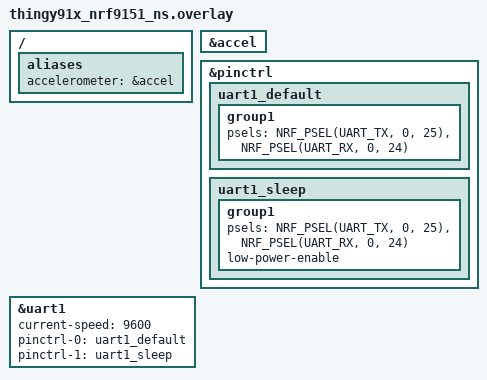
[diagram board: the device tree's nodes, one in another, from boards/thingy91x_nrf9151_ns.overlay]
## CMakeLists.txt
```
cmake_minimum_required(VERSION 3.20.0)

set(CMAKE_CXX_STANDARD 11)
set(CMAKE_CXX_STANDARD_REQUIRED ON)

find_package(Zephyr REQUIRED HINTS $ENV{ZEPHYR_BASE})

project(firmware-nordic-thingy91x)

zephyr_compile_definitions(PROJECT_NAME=${PROJECT_NAME})

# Needed for colorful output
zephyr_compile_options(-fdiagnostics-color=always)

# Do not quantize filterbank
# Enable manual loop unrolling in DSP functions
add_definitions(-DEIDSP_QUANTIZE_FILTERBANK=0
                -DARM_MATH_LOOPUNROLL
                )

# Add all required source files
add_subdirectory(ei-model/edge-impulse-sdk/cmake/zephyr)
add_subdirectory(firmware-sdk)
add_subdirectory(src/inference)
add_subdirectory(src/sensors)
add_subdirectory(src)

# Include directories (everything in the SDK is already included here)
target_include_directories(app PRIVATE .)
target_include_directories(app PRIVATE ei-model)

# Use GLOB to include model files, because model file names differes whether model is EON compiled or not
RECURSIVE_FIND_FILE(MODEL_FILES ei-model/tflite-model "*.cpp")
target_sources(app PRIVATE ${MODEL_FILES})
```

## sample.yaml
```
sample:
  name: Fall Detection GPS Emergency Alert System
  description: Edge Impulse fall detection with LoRaWAN GPS emergency alerts
tests:
  sample.fall_detection_gps_tracker:
    integration_platforms:
      - thingy91x/nrf9151/ns
    tags:
      - sensors
      - accelerometer
      - gnss
      - lorawan
      - ml
      - fall_detection
      - emergency_alert
    filter: CONFIG_ADXL367 and CONFIG_NRF_MODEM_LIB and CONFIG_UART_ASYNC_API
    harness: keyboard
```

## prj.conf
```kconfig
# /* The Clear BSD License
#  *
#  * Copyright (c) 2025 EdgeImpulse Inc.
#  * All rights reserved.
#  *
#  * Redistribution and use in source and binary forms, with or without
#  * modification, are permitted (subject to the limitations in the disclaimer
#  * below) provided that the following conditions are met:
#  *
#  *   * Redistributions of source code must retain the above copyright notice,
#  *   this list of conditions and the following disclaimer.
#  *
#  *   * Redistributions in binary form must reproduce the above copyright
#  *   notice, this list of conditions and the following disclaimer in the
#  *   documentation and/or other materials provided with the distribution.
#  *
#  *   * Neither the name of the copyright holder nor the names of its
#  *   contributors may be used to endorse or promote products derived from this
#  *   software without specific prior written permission.
#  *
#  * NO EXPRESS OR IMPLIED LICENSES TO ANY PARTY'S PATENT RIGHTS ARE GRANTED BY
#  * THIS LICENSE. THIS SOFTWARE IS PROVIDED BY THE COPYRIGHT HOLDERS AND
#  * CONTRIBUTORS "AS IS" AND ANY EXPRESS OR IMPLIED WARRANTIES, INCLUDING, BUT NOT
#  * LIMITED TO, THE IMPLIED WARRANTIES OF MERCHANTABILITY AND FITNESS FOR A
#  * PARTICULAR PURPOSE ARE DISCLAIMED. IN NO EVENT SHALL THE COPYRIGHT HOLDER OR
#  * CONTRIBUTORS BE LIABLE FOR ANY DIRECT, INDIRECT, INCIDENTAL, SPECIAL,
#  * EXEMPLARY, OR CONSEQUENTIAL DAMAGES (INCLUDING, BUT NOT LIMITED TO,
#  * PROCUREMENT OF SUBSTITUTE GOODS OR SERVICES; LOSS OF USE, DATA, OR PROFITS; OR
#  * BUSINESS INTERRUPTION) HOWEVER CAUSED AND ON ANY THEORY OF LIABILITY, WHETHER
#  * IN CONTRACT, STRICT LIABILITY, OR TORT (INCLUDING NEGLIGENCE OR OTHERWISE)
#  * ARISING IN ANY WAY OUT OF THE USE OF THIS SOFTWARE, EVEN IF ADVISED OF THE
#  * POSSIBILITY OF SUCH DAMAGE.
#  */

#
# Combined EdgeImpulse + LoRaWAN + GNSS Configuration
# Using working LoRa project as base for GPS functionality
#

# Bootloader (from working LoRa base)
CONFIG_BOOTLOADER_MCUBOOT=y

# Basic system configuration (optimized from working EdgeImpulse + LoRa + GPS)
CONFIG_MAIN_STACK_SIZE=4096
CONFIG_SYSTEM_WORKQUEUE_STACK_SIZE=4096
CONFIG_HEAP_MEM_POOL_SIZE=60000

# UART configuration (from working LoRa base - keep async for LoRa-E5)
CONFIG_SERIAL=y
CONFIG_UART_NRFX=y
CONFIG_UART_ASYNC_API=y

# GPIO for LED control (from working LoRa base)
CONFIG_GPIO=y

# Standard C library support (EdgeImpulse + working LoRa base)
CONFIG_NEWLIB_LIBC=y
CONFIG_NEWLIB_LIBC_NANO=y
CONFIG_NEWLIB_LIBC_FLOAT_PRINTF=y
CONFIG_ASSERT=y
CONFIG_REBOOT=y
CONFIG_FPU=y
CONFIG_CPP=y
CONFIG_GLIBCXX_LIBCPP=y
CONFIG_BOOT_BANNER=n
CONFIG_COMPILER_WARNINGS_AS_ERRORS=n

# Logging configuration (from working LoRa base)
CONFIG_LOG=y
CONFIG_LOG_DEFAULT_LEVEL=3
CONFIG_PRINTK=y
CONFIG_CONSOLE=y
CONFIG_UART_CONSOLE=y

# EdgeImpulse specific
CONFIG_LOG_MODE_DEFERRED=y
CONFIG_CBPRINTF_PACKAGE_LOG_LEVEL_OFF=y
CONFIG_FLASH_LOG_LEVEL_OFF=y
CONFIG_SENSOR_LOG_LEVEL_OFF=y
CONFIG_HW_STACK_PROTECTION=y

# Disable MCUboot DFU -- incompatible with static partitions (EdgeImpulse)
CONFIG_SECURE_BOOT=n

# Flash - Used in FOTA, settings and storage for P-GPS (EdgeImpulse)
CONFIG_FLASH=y
CONFIG_FLASH_PAGE_LAYOUT=y
CONFIG_FLASH_MAP=y
CONFIG_STREAM_FLASH=y
CONFIG_MPU_ALLOW_FLASH_WRITE=y

# LEDs (EdgeImpulse)
CONFIG_LED=y
CONFIG_LED_GPIO=y

# Sensors (EdgeImpulse)
CONFIG_SENSOR=y
CONFIG_ADXL367=y

# Power Management (EdgeImpulse)
CONFIG_REGULATOR=y

# GNSS support (EXACT from working LoRa project)
CONFIG_NRF_MODEM_LIB=y
CONFIG_LTE_LINK_CONTROL=y
CONFIG_LTE_NETWORK_MODE_LTE_M_GPS=y

# Networking for GNSS (EXACT copy from working LoRa project)
CONFIG_NETWORKING=y
CONFIG_NET_SOCKETS_OFFLOAD=y
CONFIG_NET_SOCKETS=y
CONFIG_NET_NATIVE=n

# POSIX support - minimal to avoid syscall issues
CONFIG_POSIX_API=n

# Basic AT Host support (from working LoRa project)
CONFIG_AT_HOST_LIBRARY=y

# Watchdog for reliability (from working LoRa project)
CONFIG_WATCHDOG=y

# EdgeImpulse specific - polling support for GNSS event handling
CONFIG_POLL=y

# Modem info (EdgeImpulse)
CONFIG_MODEM_INFO=y
```

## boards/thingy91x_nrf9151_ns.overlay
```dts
/*
 * Copyright (c) 2021 Nordic Semiconductor ASA
 *
 * SPDX-License-Identifier: LicenseRef-Nordic-5-Clause
 */

/ {
	aliases {
		accelerometer = &accel;
	};
};

&accel {
	status = "okay";
};

// UART1 configuration for LoRa-E5 module
&pinctrl {
    uart1_default: uart1_default {
        group1 {
            psels = <NRF_PSEL(UART_TX, 0, 25)>,
                    <NRF_PSEL(UART_RX, 0, 24)>;
        };
    };

    uart1_sleep: uart1_sleep {
        group1 {
            psels = <NRF_PSEL(UART_TX, 0, 25)>,
                    <NRF_PSEL(UART_RX, 0, 24)>;
            low-power-enable;
        };
    };
};

&uart1 {
    status = "okay";
    current-speed = <9600>;
    pinctrl-0 = <&uart1_default>;
    pinctrl-1 = <&uart1_sleep>;
    pinctrl-names = "default", "sleep";
};
```

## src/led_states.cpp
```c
#include "led_states.h"
#include <zephyr/logging/log.h>

LOG_MODULE_REGISTER(led_states, CONFIG_LOG_DEFAULT_LEVEL);

// Global variables
static const struct device *gpio_dev = NULL;
static bool led_initialized = false;
static bool background_task_running __attribute__((unused)) = false;
static led_state_t current_state = LED_STATE_ALL_OFF;

// Background thread for LED patterns (unused for now)
static struct k_thread led_thread __attribute__((unused));
static K_THREAD_STACK_DEFINE(led_thread_stack, 1024) __attribute__((unused));

// Mutex for LED operations
K_MUTEX_DEFINE(led_mutex);

// Initialize LED subsystem
void led_init(void)
{
    gpio_dev = DEVICE_DT_GET(DT_NODELABEL(gpio0));
    if (!device_is_ready(gpio_dev)) {
        LOG_ERR("GPIO device not ready for LEDs");
        return;
    }

    // Configure LED pins as outputs (active low)
    gpio_pin_configure(gpio_dev, LED_RED_PIN, GPIO_OUTPUT_INACTIVE);
    gpio_pin_configure(gpio_dev, LED_GREEN_PIN, GPIO_OUTPUT_INACTIVE);
    gpio_pin_configure(gpio_dev, LED_BLUE_PIN, GPIO_OUTPUT_INACTIVE);

    led_initialized = true;
    LOG_INF("LED system initialized");
}

// Set individual LED color (Thingy:91 X LEDs are active HIGH)
void led_set_color(bool red, bool green, bool blue)
{
    if (!led_initialized) return;

    k_mutex_lock(&led_mutex, K_FOREVER);

    gpio_pin_set(gpio_dev, LED_RED_PIN, red ? 1 : 0);    // Active HIGH: 1=ON, 0=OFF
    gpio_pin_set(gpio_dev, LED_GREEN_PIN, green ? 1 : 0); // Active HIGH: 1=ON, 0=OFF
    gpio_pin_set(gpio_dev, LED_BLUE_PIN, blue ? 1 : 0);   // Active HIGH: 1=ON, 0=OFF

    k_mutex_unlock(&led_mutex);
}

// Turn off all LEDs
void led_all_off(void)
{
    led_set_color(false, false, false);
}

// Simple blink functions for specific colors
void led_blink_red(uint32_t count, uint32_t duration_ms, uint32_t delay_ms)
{
    for (uint32_t i = 0; i < count; i++) {
        led_set_color(true, false, false);
        k_msleep(duration_ms);
        led_all_off();
        if (i < count - 1) k_msleep(delay_ms);
    }
}

void led_blink_green(uint32_t count, uint32_t duration_ms, uint32_t delay_ms)
{
    for (uint32_t i = 0; i < count; i++) {
        led_set_color(false, true, false);
        k_msleep(duration_ms);
        led_all_off();
        if (i < count - 1) k_msleep(delay_ms);
    }
}

void led_blink_blue(uint32_t count, uint32_t duration_ms, uint32_t delay_ms)
{
    for (uint32_t i = 0; i < count; i++) {
        led_set_color(false, false, true);
        k_msleep(duration_ms);
        led_all_off();
        if (i < count - 1) k_msleep(delay_ms);
    }
}

void led_blink_yellow(uint32_t count, uint32_t duration_ms, uint32_t delay_ms)
{
    for (uint32_t i = 0; i < count; i++) {
        led_set_color(true, true, false);  // Red + Green = Yellow
        k_msleep(duration_ms);
        led_all_off();
        if (i < count - 1) k_msleep(delay_ms);
    }
}

void led_blink_cyan(uint32_t count, uint32_t duration_ms, uint32_t delay_ms)
{
    for (uint32_t i = 0; i < count; i++) {
        led_set_color(false, true, true);  // Green + Blue = Cyan
        k_msleep(duration_ms);
        led_all_off();
        if (i < count - 1) k_msleep(delay_ms);
    }
}

void led_blink_magenta(uint32_t count, uint32_t duration_ms, uint32_t delay_ms)
{
    for (uint32_t i = 0; i < count; i++) {
        led_set_color(true, false, true);  // Red + Blue = Magenta
        k_msleep(duration_ms);
        led_all_off();
        if (i < count - 1) k_msleep(delay_ms);
    }
}

void led_blink_white(uint32_t count, uint32_t duration_ms, uint32_t delay_ms)
{
    for (uint32_t i = 0; i < count; i++) {
        led_set_color(true, true, true);  // All colors = White
        k_msleep(duration_ms);
        led_all_off();
        if (i < count - 1) k_msleep(delay_ms);
    }
}

// Solid color functions
void led_solid_green(uint32_t duration_ms)
{
    led_set_color(false, true, false);
    k_msleep(duration_ms);
    led_all_off();
}

void led_solid_red(uint32_t duration_ms)
{
    led_set_color(true, false, false);
    k_msleep(duration_ms);
    led_all_off();
}

// Emergency flash pattern
void led_emergency_flash(void)
{
    // Urgent red flashing pattern
    for (int i = 0; i < 10; i++) {
        led_set_color(true, false, false);
        k_msleep(100);
        led_all_off();
        k_msleep(100);
    }
    k_msleep(500);
    for (int i = 0; i < 10; i++) {
        led_set_color(true, false, false);
        k_msleep(100);
        led_all_off();
        k_msleep(100);
    }
}

// Breathing effect for operational state
void led_breathing_effect(void)
{
    // Gentle green breathing effect
    for (int brightness = 0; brightness < 100; brightness += 5) {
        led_set_color(false, true, false);
        k_msleep(10);
        led_all_off();
        k_msleep(50);
    }
    for (int brightness = 100; brightness > 0; brightness -= 5) {
        led_set_color(false, true, false);
        k_msleep(10);
        led_all_off();
        k_msleep(50);
    }
}

// Main LED state function
void led_set_state(led_state_t state)
{
    if (!led_initialized) return;

    current_state = state;

    switch (state) {
        case LED_STATE_SYSTEM_INIT:
            // White blink - system initializing
            led_blink_white(3, 200, 200);
            break;

        case LED_STATE_SYSTEM_READY:
            // Solid green for 2 seconds - all systems ready
            led_solid_green(2000);
            break;

        case LED_STATE_SYSTEM_ERROR:
            // Solid red - critical error
            led_set_color(true, false, false);
            break;

        // LoRa states
        case LED_STATE_LORA_INITIALIZING:
            // Yellow slow blink
            led_blink_yellow(5, 300, 500);
            break;

        case LED_STATE_LORA_INIT_SUCCESS:
            // Green blink
            led_blink_green(2, 200, 200);
            break;

        case LED_STATE_LORA_INIT_FAILED:
            // Red fast blink
            led_blink_red(5, 100, 100);
            break;

        case LED_STATE_LORA_JOINING:
            // Orange slow blink (red + green with timing)
            for (int i = 0; i < 5; i++) {
                led_set_color(true, true, false);
                k_msleep(400);
                led_all_off();
                k_msleep(600);
            }
            break;

        case LED_STATE_LORA_JOINED:
            // Green double blink
            led_blink_green(2, 150, 150);
            k_msleep(300);
            led_blink_green(2, 150, 150);
            break;

        case LED_STATE_LORA_JOIN_FAILED:
            // Red double blink
            led_blink_red(2, 150, 150);
            k_msleep(300);
            led_blink_red(2, 150, 150);
            break;

        case LED_STATE_LORA_SENDING:
            // Blue fast blink
            led_blink_blue(8, 50, 50);
            break;

        case LED_STATE_LORA_SEND_SUCCESS:
            // Green triple blink
            led_blink_green(3, 100, 100);
            break;

        case LED_STATE_LORA_SEND_FAILED:
            // Red triple blink
            led_blink_red(3, 100, 100);
            break;

        // GPS states
        case LED_STATE_GPS_INITIALIZING:
            // Cyan slow blink
            led_blink_cyan(5, 300, 500);
            break;

        case LED_STATE_GPS_INIT_SUCCESS:
            // Green blink
            led_blink_green(1, 300, 0);
            break;

        case LED_STATE_GPS_INIT_FAILED:
            // Red blink
            led_blink_red(1, 300, 0);
            break;

        case LED_STATE_GPS_SEARCHING:
            // Purple slow blink
            led_blink_magenta(1, 500, 1000);
            break;

        case LED_STATE_GPS_FIX_ACQUIRED:
            // Green solid for 2 seconds
            led_solid_green(2000);
            break;

        case LED_STATE_GPS_FIX_LOST:
            // Orange blink
            for (int i = 0; i < 3; i++) {
                led_set_color(true, true, false);
                k_msleep(200);
                led_all_off();
                k_msleep(200);
            }
            break;

        case LED_STATE_GPS_TIMEOUT:
            // Red slow blink
            led_blink_red(3, 500, 500);
            break;

        // ML states
        case LED_STATE_ML_INITIALIZING:
            // Magenta slow blink
            led_blink_magenta(5, 300, 300);
            break;

        case LED_STATE_ML_READY:
            // Green single blink
            led_blink_green(1, 200, 0);
            break;

        case LED_STATE_ML_INFERENCING:
            // Blue very fast blink
            led_blink_blue(1, 50, 0);
            break;

        case LED_STATE_ML_IDLE_DETECTED:
            // Blue dim (short pulse)
            led_blink_blue(1, 10, 0);
            break;

        case LED_STATE_ML_ACTIVE_DETECTED:
            // Blue bright (longer pulse)
            led_blink_blue(1, 100, 0);
            break;

        case LED_STATE_ML_ERROR:
            // Red blink
            led_blink_red(1, 200, 0);
            break;

        // Emergency states
        case LED_STATE_FALL_DETECTED:
            // Urgent red flashing
            led_emergency_flash();
            break;

        case LED_STATE_EMERGENCY_ALERT_SENT:
            // Red + Green alternating
            for (int i = 0; i < 6; i++) {
                led_set_color(true, false, false);
                k_msleep(150);
                led_set_color(false, true, false);
                k_msleep(150);
            }
            led_all_off();
            break;

        case LED_STATE_EMERGENCY_ALERT_FAILED:
            // Red continuous for 3 seconds
            led_set_color(true, false, false);
            k_msleep(3000);
            led_all_off();
            break;

        case LED_STATE_EMERGENCY_COOLDOWN:
            // Orange dim
            led_set_color(true, true, false);
            k_msleep(100);
            led_all_off();
            break;

        // Location transmission states
        case LED_STATE_LOCATION_ROUTINE_SENT:
            // Blue triple blink
            led_blink_blue(3, 100, 100);
            break;

        case LED_STATE_LOCATION_EMERGENCY_SENT:
            // Red + Blue alternating
            for (int i = 0; i < 4; i++) {
                led_set_color(true, false, false);
                k_msleep(100);
                led_set_color(false, false, true);
                k_msleep(100);
            }
            led_all_off();
            break;

        case LED_STATE_LOCATION_SEND_FAILED:
            // Red + Orange alternating
            for (int i = 0; i < 3; i++) {
                led_set_color(true, false, false);
                k_msleep(150);
                led_set_color(true, true, false);
                k_msleep(150);
            }
            led_all_off();
            break;

        case LED_STATE_ALL_OFF:
        default:
            led_all_off();
            break;
    }
}
```

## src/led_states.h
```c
#ifndef LED_STATES_H
#define LED_STATES_H

#include <zephyr/kernel.h>
#include <zephyr/drivers/gpio.h>

#ifdef __cplusplus
extern "C" {
#endif

// LED State Management System for Fall Detection + GPS Emergency Alert System

// LED pin definitions (Thingy:91 X) - corrected mapping: P29=RED, P31=GREEN, P30=BLUE
#define LED_RED_PIN   29  // P0.29 controls RED LED
#define LED_GREEN_PIN 31  // P0.31 controls GREEN LED
#define LED_BLUE_PIN  30  // P0.30 controls BLUE LED

// System state definitions
typedef enum {
    // System states
    LED_STATE_SYSTEM_INIT,              // White (all colors) - System initializing
    LED_STATE_SYSTEM_READY,             // Green solid - All systems operational
    LED_STATE_SYSTEM_ERROR,             // Red solid - Critical system error

    // LoRa states
    LED_STATE_LORA_INITIALIZING,        // Yellow slow blink - LoRa module initializing
    LED_STATE_LORA_INIT_SUCCESS,        // Green blink - LoRa initialized successfully
    LED_STATE_LORA_INIT_FAILED,         // Red fast blink - LoRa initialization failed
    LED_STATE_LORA_JOINING,             // Orange slow blink - Joining LoRaWAN network
    LED_STATE_LORA_JOINED,              // Green double blink - Successfully joined network
    LED_STATE_LORA_JOIN_FAILED,         // Red double blink - Failed to join network
    LED_STATE_LORA_SENDING,             // Blue fast blink - Sending data
    LED_STATE_LORA_SEND_SUCCESS,        // Green triple blink - Data sent successfully
    LED_STATE_LORA_SEND_FAILED,         // Red triple blink - Data send failed

    // GPS states
    LED_STATE_GPS_INITIALIZING,         // Cyan slow blink - GPS initializing
    LED_STATE_GPS_INIT_SUCCESS,         // Green blink - GPS initialized
    LED_STATE_GPS_INIT_FAILED,          // Red blink - GPS initialization failed
    LED_STATE_GPS_SEARCHING,            // Purple slow blink - Searching for GPS fix
    LED_STATE_GPS_FIX_ACQUIRED,         // Green solid 2s - GPS fix acquired
    LED_STATE_GPS_FIX_LOST,             // Orange blink - GPS fix lost
    LED_STATE_GPS_TIMEOUT,              // Red slow blink - GPS fix timeout

    // Edge Impulse / ML states
    LED_STATE_ML_INITIALIZING,          // Magenta slow blink - ML system initializing
    LED_STATE_ML_READY,                 // Green blink - ML system ready
    LED_STATE_ML_INFERENCING,           // Blue very fast blink - Running inference
    LED_STATE_ML_IDLE_DETECTED,         // Blue dim - Idle state detected
    LED_STATE_ML_ACTIVE_DETECTED,       // Blue bright - Active state detected
    LED_STATE_ML_ERROR,                 // Red blink - ML system error

    // Emergency states
    LED_STATE_FALL_DETECTED,            // Red urgent flash - Fall detected!
    LED_STATE_EMERGENCY_ALERT_SENT,     // Red + Green alternate - Emergency alert sent
    LED_STATE_EMERGENCY_ALERT_FAILED,   // Red continuous - Emergency alert failed
    LED_STATE_EMERGENCY_COOLDOWN,       // Orange dim - Emergency cooldown active

    // Location transmission states
    LED_STATE_LOCATION_ROUTINE_SENT,    // Blue triple blink - Routine location sent
    LED_STATE_LOCATION_EMERGENCY_SENT,  // Red + Blue alternate - Emergency location sent
    LED_STATE_LOCATION_SEND_FAILED,     // Red + Orange alternate - Location send failed

    // Special states
    LED_STATE_ALL_OFF,                  // All LEDs off
    LED_STATE_BREATHING,                // Gentle breathing effect (operational)

} led_state_t;

// LED control structure
typedef struct {
    bool red_on;
    bool green_on;
    bool blue_on;
    uint32_t duration_ms;
    uint32_t repeat_count;
    uint32_t delay_between_ms;
} led_pattern_t;

// Function declarations
void led_init(void);
void led_set_state(led_state_t state);
void led_set_color(bool red, bool green, bool blue);
void led_blink_pattern(led_pattern_t *pattern);
void led_emergency_flash(void);
void led_breathing_effect(void);
void led_all_off(void);

// Utility functions for common patterns
void led_blink_red(uint32_t count, uint32_t duration_ms, uint32_t delay_ms);
void led_blink_green(uint32_t count, uint32_t duration_ms, uint32_t delay_ms);
void led_blink_blue(uint32_t count, uint32_t duration_ms, uint32_t delay_ms);
void led_blink_yellow(uint32_t count, uint32_t duration_ms, uint32_t delay_ms);
void led_blink_cyan(uint32_t count, uint32_t duration_ms, uint32_t delay_ms);
void led_blink_magenta(uint32_t count, uint32_t duration_ms, uint32_t delay_ms);
void led_blink_white(uint32_t count, uint32_t duration_ms, uint32_t delay_ms);
void led_solid_green(uint32_t duration_ms);
void led_solid_red(uint32_t duration_ms);

// Background LED state management
void led_start_background_task(void);
void led_stop_background_task(void);

#ifdef __cplusplus
}
#endif

#endif // LED_STATES_H
```
